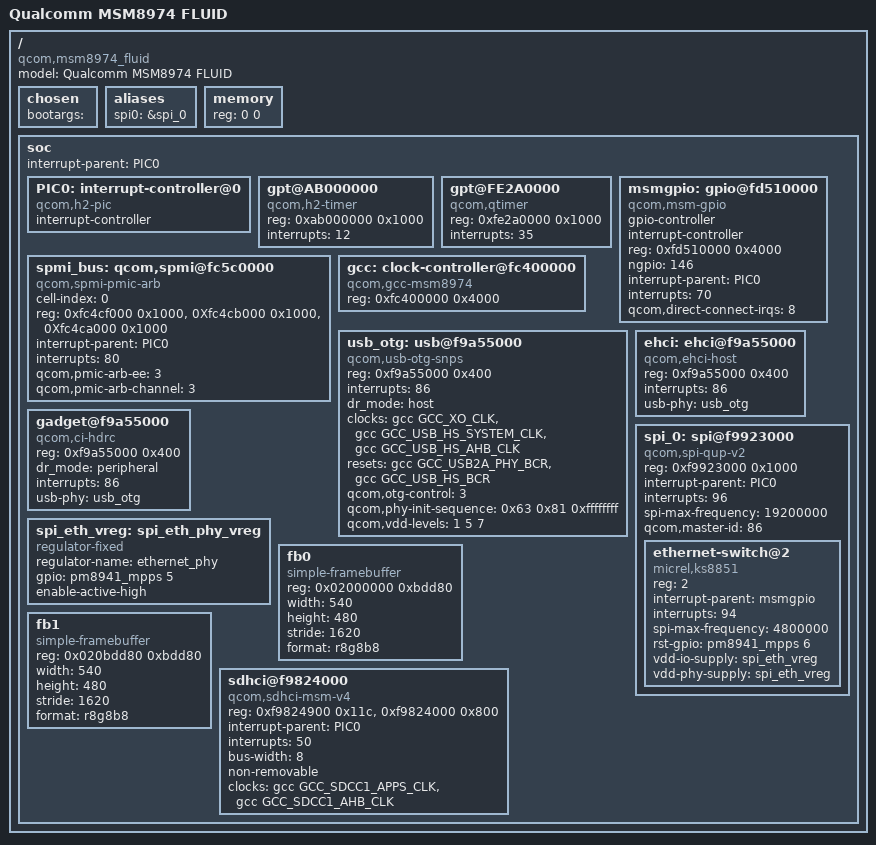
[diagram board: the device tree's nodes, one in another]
/dts-v1/;

#include <dt-bindings/clock/qcom,gcc-msm8974.h>
#include <dt-bindings/reset/qcom,gcc-msm8974.h>

/*  Bare minimum  */
/ {
	#address-cells = <1>;
	#size-cells = <1>;
	chosen { };
	aliases {
                spi0 = &spi_0;
	};
	memory { device_type = "memory"; reg = <0 0>; };

	/*  note:  framebuffer is currently at 0x8900_0000; 1024*600*3 */
};


/ {
	chosen {
		bootargs = "";
	};
};


/ {
        model = "Qualcomm MSM8974 FLUID";
        compatible = "qcom,msm8974_fluid";

	soc: soc {
		#address-cells = <1>;
		#size-cells = <1>;
		ranges;
		interrupt-parent = <&PIC0>;

		PIC0: interrupt-controller@0 {
			compatible = "qcom,h2-pic";
			interrupt-controller;
			#interrupt-cells = <1>;
		};

		gpt@AB000000 {
			compatible="qcom,h2-timer";
			reg = <0xab000000 0x1000>;
			interrupts = <12>;   /*  interrupts CPU directly; rising edge triggered */
		};

		gpt@FE2A0000 {
			compatible="qcom,qtimer";
			reg = <0xfe2a0000 0x1000>;
			interrupts = <35>;
		};

		msmgpio: gpio@fd510000 {
			compatible = "qcom,msm-gpio";
			gpio-controller;
			#gpio-cells = <2>;
			interrupt-controller;
			#interrupt-cells = <2>;
			reg = <0xfd510000 0x4000>;	/* hrm, prlly need to make sure platform io.c does this right  */
			ngpio = <146>;
			interrupt-parent = <&PIC0>;
			interrupts = <70>;		/* LPASS Spreadsheet calls it "summary_irq_apcs_dsp", aka "summary_irq_lpa_dsp"; l2vic[38] + L1_ints (32); active high; do not confuse with ethernet; do not confuse with the sensors IRQ which I won't be using.  DON'T BE CONFUSED.  */
			qcom,direct-connect-irqs = <8>;	/* apparently 8 direct connectable IRQ's  */
		};

		spmi_bus: qcom,spmi@fc5c0000 {
			cell-index = <0>;
			compatible = "qcom,spmi-pmic-arb";
			reg-names = "core", "intr", "cnfg";
			reg = <0xfc4cf000 0x1000>,
			      <0Xfc4cb000 0x1000>,
			      <0Xfc4ca000 0x1000>;
			/* 190,ee0_krait_hlos_spmi_periph_irq */
			/* 187,channel_0_krait_hlos_trans_done_irq */
			/* This might be 48+32 ee3_lpass_spmi_periph_irq */
			/* This might be 49+32 channel3_lpass_trans_done_irq */
			/* EE is "execution environment"?  */
			/*  interrupts = <0 190 0 0 187 0>;  */
			interrupt-parent = <&PIC0>;
			interrupts = <80>;
			qcom,pmic-arb-ee = <3>;
			qcom,pmic-arb-channel = <3>;
		};

		gcc: clock-controller@fc400000 {
			compatible = "qcom,gcc-msm8974", "qcom,gcc";
			#clock-cells = <1>;
			#reset-cells = <1>;
			/*  This is a real physical address; make sure it's not in map_io or whatever  */
			reg = <0xfc400000 0x4000>;
		};

		usb_otg: usb@f9a55000 {
			compatible = "qcom,usb-otg-snps";
			reg = <0xf9a55000 0x400>;
			interrupts = <86>;  /*  54 + 32  */
			dr_mode = "host";

			clocks = <&gcc GCC_XO_CLK>, <&gcc GCC_USB_HS_SYSTEM_CLK>, <&gcc GCC_USB_HS_AHB_CLK>;
			clock-names = "phy", "core", "iface";

			/*  vddcx-supply = <&pm8841_s2_corner>;  not supported yet */
			/*  v1p8-supply = <&pm8941_l6>;  not supported yet  */
			/*  v3p3-supply = <&pm8941_l24>;  not supoprted yet  */

			resets = <&gcc GCC_USB2A_PHY_BCR>, <&gcc GCC_USB_HS_BCR>;
			reset-names = "phy", "link";

			qcom,otg-control = <3>;
			qcom,phy-init-sequence = <0x63 0x81 0xffffffff>;
			qcom,vdd-levels = <1 5 7>;
		};

		ehci: ehci@f9a55000 {
			compatible = "qcom,ehci-host";
			reg = <0xf9a55000 0x400>;
			interrupts = <86>;  /*  54 + 32  */
			usb-phy = <&usb_otg>;
			status="ok";
		};

		gadget@f9a55000 {
			compatible = "qcom,ci-hdrc";
			reg = <0xf9a55000 0x400>;
			dr_mode = "peripheral";
			interrupts = <86>;  /*  54 + 32  */
			usb-phy = <&usb_otg>;
		};
			/*  l2vic[18] + L1_ints (32);  rising edge?  */
			/*  l2vic[8] + L1_ints (32);  rising edge?  */
			/*  l2vic[33] + L1_ints (32);  rising edge?  */
			/*  l2vic[46] + L1_ints (32);  rising edge?  */
/*
		irqtest {
			compatible = "qcom,hexagon-irqtest";
			interrupt-parent = <&PIC0>;
			interrupts = <50 0>, <40 0>, <65 0>, <78 0>;
		};
*/

	};
};


#include <msm-pm8941.dtsi>

&soc {
	spi_eth_vreg: spi_eth_phy_vreg {
		compatible = "regulator-fixed";
		regulator-name = "ethernet_phy";
		gpio = <&pm8941_mpps 5 0>;
		enable-active-high;
	};

	spi_0: spi@f9923000 {
		compatible = "qcom,spi-qup-v2";
		reg = <0xf9923000 0x1000>;
		interrupt-parent = <&PIC0>;
		interrupts = <96>;	/*  l2vic[64] + L1_ints (32); active high  */
		spi-max-frequency = <19200000>;
		#address-cells = <1>;
		#size-cells = <0>;
		qcom,master-id = <86>;

		ethernet-switch@2 {
			compatible = "micrel,ks8851";
			reg = <2>;
			interrupt-parent = <&msmgpio>;
			interrupts = <94>;
			spi-max-frequency = <4800000>;
			rst-gpio = <&pm8941_mpps 6 0>;
			vdd-io-supply = <&spi_eth_vreg>;
			vdd-phy-supply = <&spi_eth_vreg>;
		};

	};

/*
	framebuffer {
		compatible = "simple-framebuffer";
		reg = <0x02000000 0x2a3000>;
		width = <540>;
		height = <960>;
		stride = <1620>;
		format = "r8g8b8";
	};
*/

	fb0 {
		compatible = "simple-framebuffer";
		reg = <0x02000000 0xbdd80>;
		width = <540>;
		height = <480>;
		stride = <1620>;
		format = "r8g8b8";
	};

	fb1 {
		compatible = "simple-framebuffer";
		reg = <0x020bdd80 0xbdd80>;
		width = <540>;
		height = <480>;
		stride = <1620>;
		format = "r8g8b8";
	};

};


&soc {
	sdhci@f9824000 {
		compatible = "qcom,sdhci-msm-v4";
		reg = <0xf9824900 0x11c>, <0xf9824000 0x800>;
		reg-names = "hc_mem", "core_mem";
		interrupt-parent = <&PIC0>;
		interrupts = <50>;

		bus-width = <8>;
		non-removable;

/*
		pinctrl-names = "default";
		pinctrl-0 = <&sdc1_clk &sdc1_cmd &sdc1_data>;
*/

		clocks = <&gcc GCC_SDCC1_APPS_CLK>, <&gcc GCC_SDCC1_AHB_CLK>;
		clock-names = "core", "iface";
	};
};
